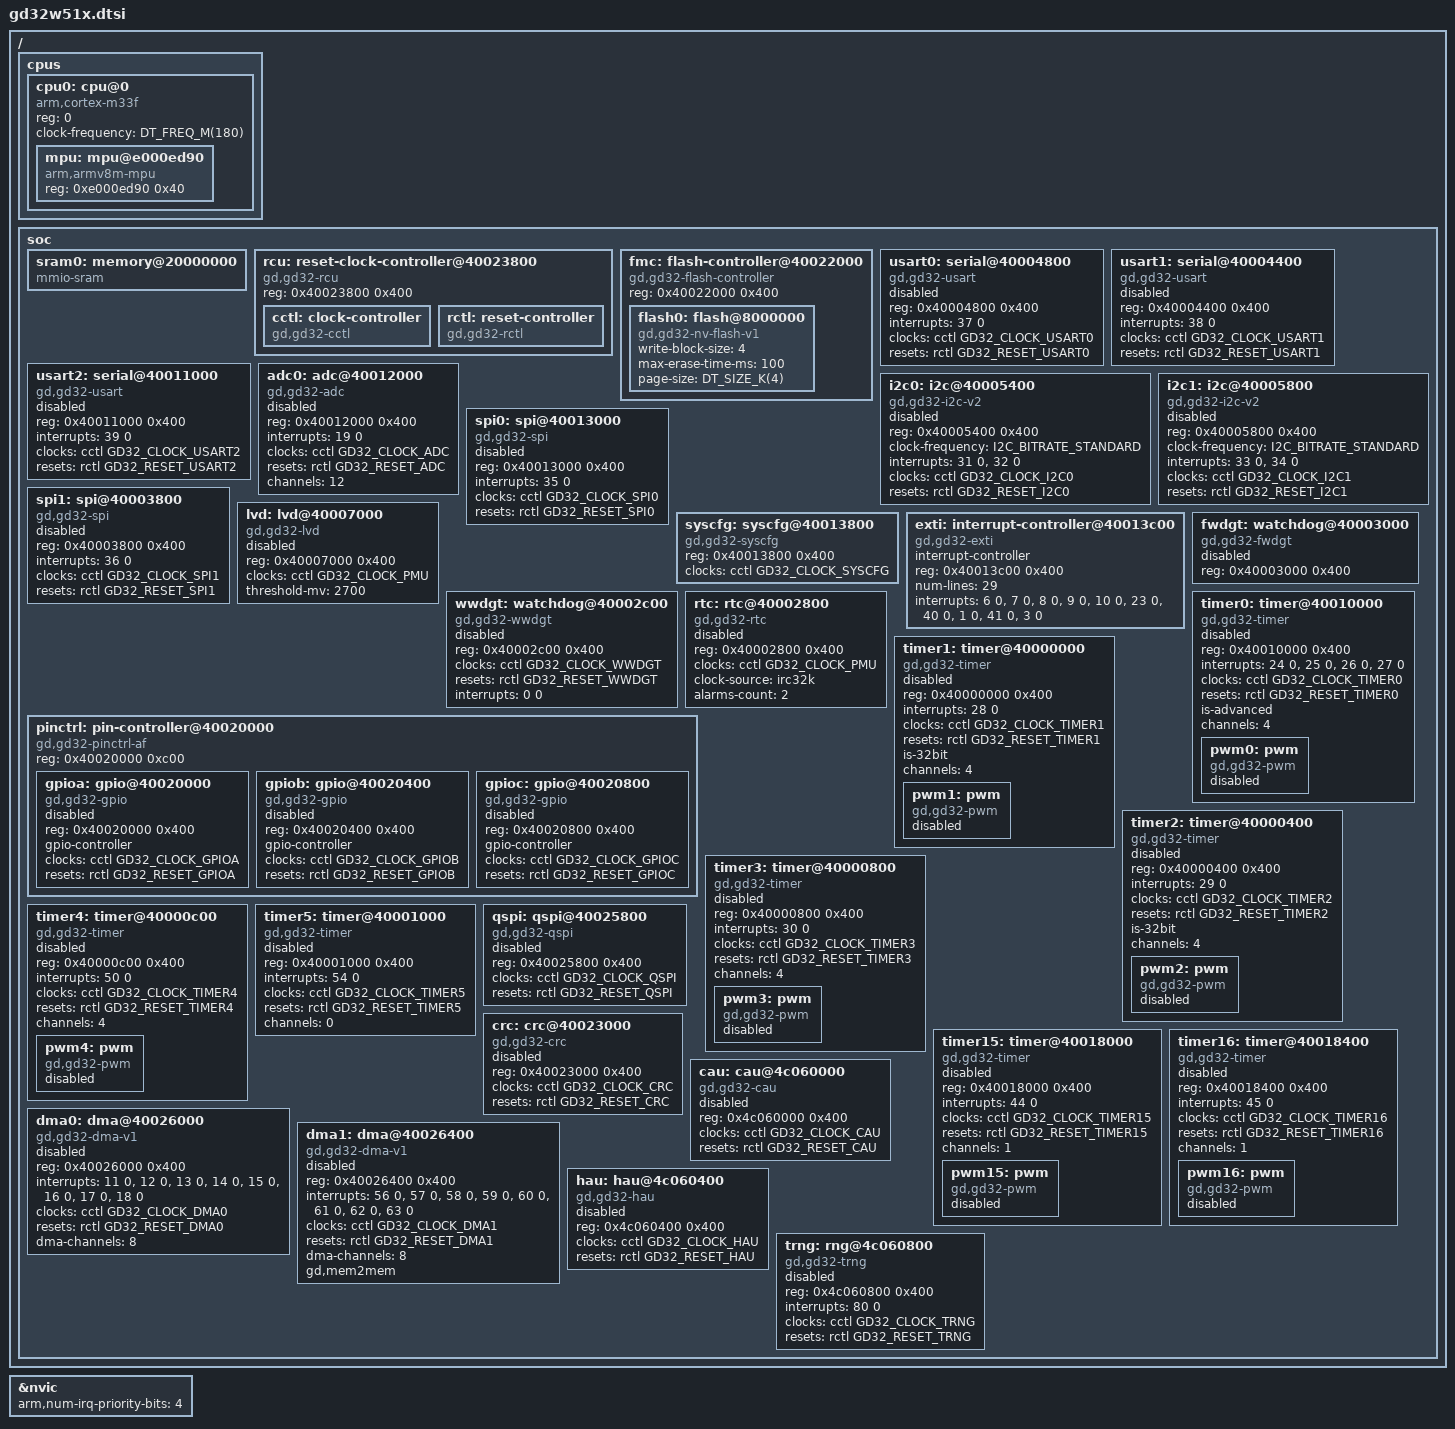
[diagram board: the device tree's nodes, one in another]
/*
 * Copyright (c) 2026 Jorge Guzman
 *
 * SPDX-License-Identifier: Apache-2.0
 */

#include <freq.h>
#include <mem.h>
#include <arm/armv8-m.dtsi>
#include <zephyr/dt-bindings/adc/adc.h>
#include <zephyr/dt-bindings/gpio/gpio.h>
#include <zephyr/dt-bindings/i2c/i2c.h>
#include <zephyr/dt-bindings/pwm/pwm.h>
#include <zephyr/dt-bindings/clock/gd32w51x-clocks.h>
#include <zephyr/dt-bindings/reset/gd32w51x.h>

/*
 * Zephyr runs as a Secure-only image with the SAU disabled. Peripherals are
 * reached through their Non-secure aliases (0x4xxxxxxx), as the HAL does.
 */

/ {
	cpus {
		#address-cells = <1>;
		#size-cells = <0>;

		cpu0: cpu@0 {
			compatible = "arm,cortex-m33f";
			reg = <0>;
			#address-cells = <1>;
			#size-cells = <1>;
			clock-frequency = <DT_FREQ_M(180)>;

			mpu: mpu@e000ed90 {
				compatible = "arm,armv8m-mpu";
				reg = <0xe000ed90 0x40>;
			};
		};
	};

	soc {
		sram0: memory@20000000 {
			compatible = "mmio-sram";
		};

		rcu: reset-clock-controller@40023800 {
			compatible = "gd,gd32-rcu";
			reg = <0x40023800 0x400>;
			status = "okay";

			cctl: clock-controller {
				compatible = "gd,gd32-cctl";
				#clock-cells = <1>;
				status = "okay";
			};

			rctl: reset-controller {
				compatible = "gd,gd32-rctl";
				#reset-cells = <1>;
				status = "okay";
			};
		};

		fmc: flash-controller@40022000 {
			compatible = "gd,gd32-flash-controller";
			reg = <0x40022000 0x400>;
			ranges;
			#address-cells = <1>;
			#size-cells = <1>;

			flash0: flash@8000000 {
				compatible = "gd,gd32-nv-flash-v1", "soc-nv-flash";
				write-block-size = <4>;
				max-erase-time-ms = <100>;
				page-size = <DT_SIZE_K(4)>;
				#address-cells = <1>;
				#size-cells = <1>;
			};
		};

		usart0: serial@40004800 {
			compatible = "gd,gd32-usart";
			reg = <0x40004800 0x400>;
			interrupts = <37 0>;
			clocks = <&cctl GD32_CLOCK_USART0>;
			resets = <&rctl GD32_RESET_USART0>;
			status = "disabled";
		};

		usart1: serial@40004400 {
			compatible = "gd,gd32-usart";
			reg = <0x40004400 0x400>;
			interrupts = <38 0>;
			clocks = <&cctl GD32_CLOCK_USART1>;
			resets = <&rctl GD32_RESET_USART1>;
			status = "disabled";
		};

		usart2: serial@40011000 {
			compatible = "gd,gd32-usart";
			reg = <0x40011000 0x400>;
			interrupts = <39 0>;
			clocks = <&cctl GD32_CLOCK_USART2>;
			resets = <&rctl GD32_RESET_USART2>;
			status = "disabled";
		};

		adc0: adc@40012000 {
			compatible = "gd,gd32-adc";
			reg = <0x40012000 0x400>;
			interrupts = <19 0>;
			clocks = <&cctl GD32_CLOCK_ADC>;
			resets = <&rctl GD32_RESET_ADC>;
			channels = <12>;
			status = "disabled";
			#io-channel-cells = <1>;
		};

		i2c0: i2c@40005400 {
			compatible = "gd,gd32-i2c-v2";
			reg = <0x40005400 0x400>;
			#address-cells = <1>;
			#size-cells = <0>;
			clock-frequency = <I2C_BITRATE_STANDARD>;
			interrupts = <31 0>, <32 0>;
			interrupt-names = "event", "error";
			clocks = <&cctl GD32_CLOCK_I2C0>;
			resets = <&rctl GD32_RESET_I2C0>;
			status = "disabled";
		};

		i2c1: i2c@40005800 {
			compatible = "gd,gd32-i2c-v2";
			reg = <0x40005800 0x400>;
			#address-cells = <1>;
			#size-cells = <0>;
			clock-frequency = <I2C_BITRATE_STANDARD>;
			interrupts = <33 0>, <34 0>;
			interrupt-names = "event", "error";
			clocks = <&cctl GD32_CLOCK_I2C1>;
			resets = <&rctl GD32_RESET_I2C1>;
			status = "disabled";
		};

		spi0: spi@40013000 {
			compatible = "gd,gd32-spi";
			reg = <0x40013000 0x400>;
			interrupts = <35 0>;
			clocks = <&cctl GD32_CLOCK_SPI0>;
			resets = <&rctl GD32_RESET_SPI0>;
			status = "disabled";
			#address-cells = <1>;
			#size-cells = <0>;
		};

		spi1: spi@40003800 {
			compatible = "gd,gd32-spi";
			reg = <0x40003800 0x400>;
			interrupts = <36 0>;
			clocks = <&cctl GD32_CLOCK_SPI1>;
			resets = <&rctl GD32_RESET_SPI1>;
			status = "disabled";
			#address-cells = <1>;
			#size-cells = <0>;
		};

		syscfg: syscfg@40013800 {
			compatible = "gd,gd32-syscfg";
			reg = <0x40013800 0x400>;
			clocks = <&cctl GD32_CLOCK_SYSCFG>;
			status = "okay";
		};

		exti: interrupt-controller@40013c00 {
			compatible = "gd,gd32-exti";
			#address-cells = <0>;
			interrupt-controller;
			#interrupt-cells = <1>;
			reg = <0x40013c00 0x400>;
			num-lines = <29>;
			interrupts = <6 0>, <7 0>, <8 0>, <9 0>, <10 0>,
				     <23 0>, <40 0>, <1 0>, <41 0>, <3 0>;
			interrupt-names = "line0", "line1", "line2", "line3",
					  "line4", "line5-9", "line10-15", "lvd",
					  "rtc-alarm", "rtc-wakeup";
			status = "okay";
		};

		lvd: lvd@40007000 {
			compatible = "gd,gd32-lvd";
			reg = <0x40007000 0x400>;
			clocks = <&cctl GD32_CLOCK_PMU>;
			threshold-mv = <2700>;
			status = "disabled";
		};

		fwdgt: watchdog@40003000 {
			compatible = "gd,gd32-fwdgt";
			reg = <0x40003000 0x400>;
			status = "disabled";
		};

		wwdgt: watchdog@40002c00 {
			compatible = "gd,gd32-wwdgt";
			reg = <0x40002c00 0x400>;
			clocks = <&cctl GD32_CLOCK_WWDGT>;
			resets = <&rctl GD32_RESET_WWDGT>;
			interrupts = <0 0>;
			status = "disabled";
		};

		rtc: rtc@40002800 {
			compatible = "gd,gd32-rtc";
			reg = <0x40002800 0x400>;
			clocks = <&cctl GD32_CLOCK_PMU>;
			clock-source = "irc32k";
			alarms-count = <2>;
			status = "disabled";
		};

		pinctrl: pin-controller@40020000 {
			compatible = "gd,gd32-pinctrl-af";
			reg = <0x40020000 0xc00>;
			#address-cells = <1>;
			#size-cells = <1>;
			status = "okay";

			gpioa: gpio@40020000 {
				compatible = "gd,gd32-gpio";
				reg = <0x40020000 0x400>;
				gpio-controller;
				#gpio-cells = <2>;
				clocks = <&cctl GD32_CLOCK_GPIOA>;
				resets = <&rctl GD32_RESET_GPIOA>;
				status = "disabled";
			};

			gpiob: gpio@40020400 {
				compatible = "gd,gd32-gpio";
				reg = <0x40020400 0x400>;
				gpio-controller;
				#gpio-cells = <2>;
				clocks = <&cctl GD32_CLOCK_GPIOB>;
				resets = <&rctl GD32_RESET_GPIOB>;
				status = "disabled";
			};

			gpioc: gpio@40020800 {
				compatible = "gd,gd32-gpio";
				reg = <0x40020800 0x400>;
				gpio-controller;
				#gpio-cells = <2>;
				clocks = <&cctl GD32_CLOCK_GPIOC>;
				resets = <&rctl GD32_RESET_GPIOC>;
				status = "disabled";
			};
		};

		timer0: timer@40010000 {
			compatible = "gd,gd32-timer";
			reg = <0x40010000 0x400>;
			interrupts = <24 0>, <25 0>, <26 0>, <27 0>;
			interrupt-names = "brk", "up", "trgcom", "cc";
			clocks = <&cctl GD32_CLOCK_TIMER0>;
			resets = <&rctl GD32_RESET_TIMER0>;
			is-advanced;
			channels = <4>;
			status = "disabled";

			pwm0: pwm {
				compatible = "gd,gd32-pwm";
				status = "disabled";
				#pwm-cells = <3>;
			};
		};

		timer1: timer@40000000 {
			compatible = "gd,gd32-timer";
			reg = <0x40000000 0x400>;
			interrupts = <28 0>;
			interrupt-names = "global";
			clocks = <&cctl GD32_CLOCK_TIMER1>;
			resets = <&rctl GD32_RESET_TIMER1>;
			is-32bit;
			channels = <4>;
			status = "disabled";

			pwm1: pwm {
				compatible = "gd,gd32-pwm";
				status = "disabled";
				#pwm-cells = <3>;
			};
		};

		timer2: timer@40000400 {
			compatible = "gd,gd32-timer";
			reg = <0x40000400 0x400>;
			interrupts = <29 0>;
			interrupt-names = "global";
			clocks = <&cctl GD32_CLOCK_TIMER2>;
			resets = <&rctl GD32_RESET_TIMER2>;
			is-32bit;
			channels = <4>;
			status = "disabled";

			pwm2: pwm {
				compatible = "gd,gd32-pwm";
				status = "disabled";
				#pwm-cells = <3>;
			};
		};

		timer3: timer@40000800 {
			compatible = "gd,gd32-timer";
			reg = <0x40000800 0x400>;
			interrupts = <30 0>;
			interrupt-names = "global";
			clocks = <&cctl GD32_CLOCK_TIMER3>;
			resets = <&rctl GD32_RESET_TIMER3>;
			channels = <4>;
			status = "disabled";

			pwm3: pwm {
				compatible = "gd,gd32-pwm";
				status = "disabled";
				#pwm-cells = <3>;
			};
		};

		timer4: timer@40000c00 {
			compatible = "gd,gd32-timer";
			reg = <0x40000c00 0x400>;
			interrupts = <50 0>;
			interrupt-names = "global";
			clocks = <&cctl GD32_CLOCK_TIMER4>;
			resets = <&rctl GD32_RESET_TIMER4>;
			channels = <4>;
			status = "disabled";

			pwm4: pwm {
				compatible = "gd,gd32-pwm";
				status = "disabled";
				#pwm-cells = <3>;
			};
		};

		timer5: timer@40001000 {
			compatible = "gd,gd32-timer";
			reg = <0x40001000 0x400>;
			interrupts = <54 0>;
			interrupt-names = "global";
			clocks = <&cctl GD32_CLOCK_TIMER5>;
			resets = <&rctl GD32_RESET_TIMER5>;
			channels = <0>;
			status = "disabled";
		};

		timer15: timer@40018000 {
			compatible = "gd,gd32-timer";
			reg = <0x40018000 0x400>;
			interrupts = <44 0>;
			interrupt-names = "global";
			clocks = <&cctl GD32_CLOCK_TIMER15>;
			resets = <&rctl GD32_RESET_TIMER15>;
			channels = <1>;
			status = "disabled";

			pwm15: pwm {
				compatible = "gd,gd32-pwm";
				status = "disabled";
				#pwm-cells = <3>;
			};
		};

		timer16: timer@40018400 {
			compatible = "gd,gd32-timer";
			reg = <0x40018400 0x400>;
			interrupts = <45 0>;
			interrupt-names = "global";
			clocks = <&cctl GD32_CLOCK_TIMER16>;
			resets = <&rctl GD32_RESET_TIMER16>;
			channels = <1>;
			status = "disabled";

			pwm16: pwm {
				compatible = "gd,gd32-pwm";
				status = "disabled";
				#pwm-cells = <3>;
			};
		};

		qspi: qspi@40025800 {
			compatible = "gd,gd32-qspi";
			reg = <0x40025800 0x400>;
			clocks = <&cctl GD32_CLOCK_QSPI>;
			resets = <&rctl GD32_RESET_QSPI>;
			#address-cells = <1>;
			#size-cells = <0>;
			status = "disabled";
		};

		crc: crc@40023000 {
			compatible = "gd,gd32-crc";
			reg = <0x40023000 0x400>;
			clocks = <&cctl GD32_CLOCK_CRC>;
			resets = <&rctl GD32_RESET_CRC>;
			status = "disabled";
		};

		dma0: dma@40026000 {
			compatible = "gd,gd32-dma-v1";
			reg = <0x40026000 0x400>;
			interrupts = <11 0>, <12 0>, <13 0>, <14 0>,
				     <15 0>, <16 0>, <17 0>, <18 0>;
			clocks = <&cctl GD32_CLOCK_DMA0>;
			resets = <&rctl GD32_RESET_DMA0>;
			dma-channels = <8>;
			#dma-cells = <4>;
			status = "disabled";
		};

		dma1: dma@40026400 {
			compatible = "gd,gd32-dma-v1";
			reg = <0x40026400 0x400>;
			interrupts = <56 0>, <57 0>, <58 0>, <59 0>,
				     <60 0>, <61 0>, <62 0>, <63 0>;
			clocks = <&cctl GD32_CLOCK_DMA1>;
			resets = <&rctl GD32_RESET_DMA1>;
			dma-channels = <8>;
			gd,mem2mem;
			#dma-cells = <4>;
			status = "disabled";
		};

		cau: cau@4c060000 {
			compatible = "gd,gd32-cau";
			reg = <0x4c060000 0x400>;
			clocks = <&cctl GD32_CLOCK_CAU>;
			resets = <&rctl GD32_RESET_CAU>;
			status = "disabled";
		};

		hau: hau@4c060400 {
			compatible = "gd,gd32-hau";
			reg = <0x4c060400 0x400>;
			clocks = <&cctl GD32_CLOCK_HAU>;
			resets = <&rctl GD32_RESET_HAU>;
			status = "disabled";
		};

		trng: rng@4c060800 {
			compatible = "gd,gd32-trng";
			reg = <0x4c060800 0x400>;
			interrupts = <80 0>;
			clocks = <&cctl GD32_CLOCK_TRNG>;
			resets = <&rctl GD32_RESET_TRNG>;
			status = "disabled";
		};
	};
};

&nvic {
	arm,num-irq-priority-bits = <4>;
};
